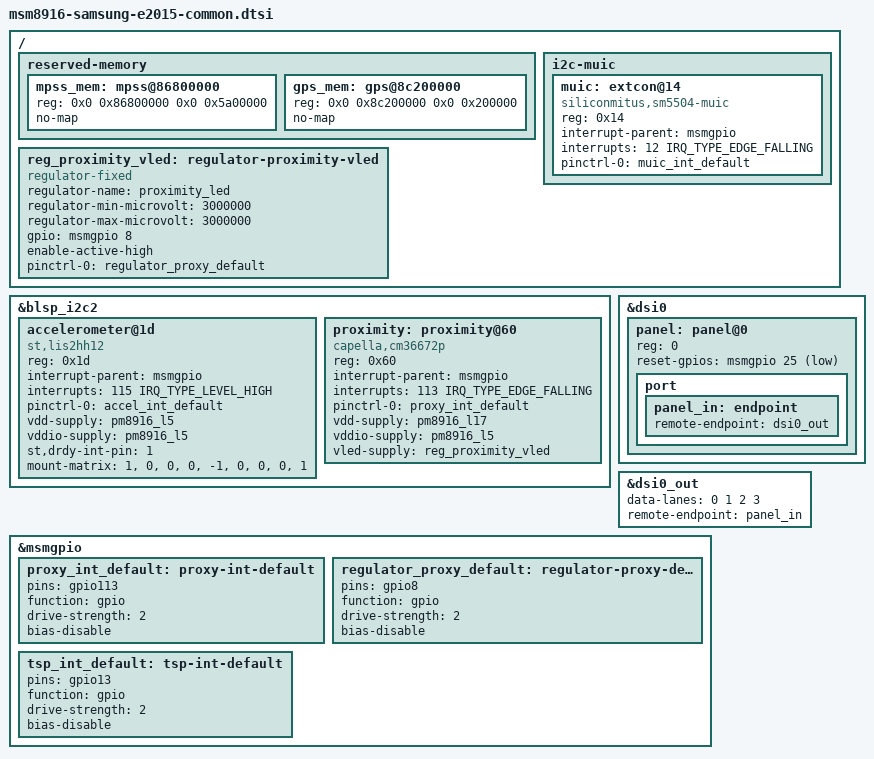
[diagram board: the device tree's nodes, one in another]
// SPDX-License-Identifier: GPL-2.0-only

#include "msm8916-samsung-a2015-common.dtsi"

/ {
	reserved-memory {
		/* Firmware for E5/E7/Grand Max needs more space */
		/delete-node/ mpss@86800000;
		/delete-node/ gps@8bc00000;

		mpss_mem: mpss@86800000 {
			reg = <0x0 0x86800000 0x0 0x5a00000>;
			no-map;
		};

		gps_mem: gps@8c200000 {
			reg = <0x0 0x8c200000 0x0 0x200000>;
			no-map;
		};
	};

	i2c-muic {
		/* SM5504 MUIC instead of SM5502 */
		/delete-node/ extcon@25;

		muic: extcon@14 {
			compatible = "siliconmitus,sm5504-muic";
			reg = <0x14>;

			interrupt-parent = <&msmgpio>;
			interrupts = <12 IRQ_TYPE_EDGE_FALLING>;

			pinctrl-names = "default";
			pinctrl-0 = <&muic_int_default>;
		};
	};

	reg_proximity_vled: regulator-proximity-vled {
		compatible = "regulator-fixed";
		regulator-name = "proximity_led";
		regulator-min-microvolt = <3000000>;
		regulator-max-microvolt = <3000000>;

		gpio = <&msmgpio 8 GPIO_ACTIVE_HIGH>;
		enable-active-high;

		pinctrl-names = "default";
		pinctrl-0 = <&regulator_proxy_default>;
	};
};

&blsp_i2c2 {
	/* lis2hh12 accelerometer instead of BMC150 */
	/delete-node/ accelerometer@10;
	/delete-node/ magnetometer@12;

	accelerometer@1d {
		compatible = "st,lis2hh12";
		reg = <0x1d>;

		interrupt-parent = <&msmgpio>;
		interrupts = <115 IRQ_TYPE_LEVEL_HIGH>;
		interrupt-names = "INT1";

		pinctrl-names = "default";
		pinctrl-0 = <&accel_int_default>;

		vdd-supply = <&pm8916_l5>;
		vddio-supply = <&pm8916_l5>;

		st,drdy-int-pin = <1>;
		mount-matrix = "1", "0", "0",
			       "0", "-1", "0",
			       "0", "0", "1";
	};

	proximity: proximity@60 {
		compatible = "capella,cm36672p";
		reg = <0x60>;

		interrupt-parent = <&msmgpio>;
		interrupts = <113 IRQ_TYPE_EDGE_FALLING>;

		pinctrl-names = "default";
		pinctrl-0 = <&proxy_int_default>;

		vdd-supply = <&pm8916_l17>;
		vddio-supply = <&pm8916_l5>;
		vled-supply = <&reg_proximity_vled>;
	};
};

&dsi0 {
	panel: panel@0 {
		reg = <0>;

		reset-gpios = <&msmgpio 25 GPIO_ACTIVE_LOW>;

		port {
			panel_in: endpoint {
				remote-endpoint = <&dsi0_out>;
			};
		};
	};
};

&dsi0_out {
	data-lanes = <0 1 2 3>;
	remote-endpoint = <&panel_in>;
};

&msmgpio {
	proxy_int_default: proxy-int-default {
		pins = "gpio113";
		function = "gpio";

		drive-strength = <2>;
		bias-disable;
	};

	regulator_proxy_default: regulator-proxy-default {
		pins = "gpio8";
		function = "gpio";

		drive-strength = <2>;
		bias-disable;
	};

	tsp_int_default: tsp-int-default {
		pins = "gpio13";
		function = "gpio";

		drive-strength = <2>;
		bias-disable;
	};
};
